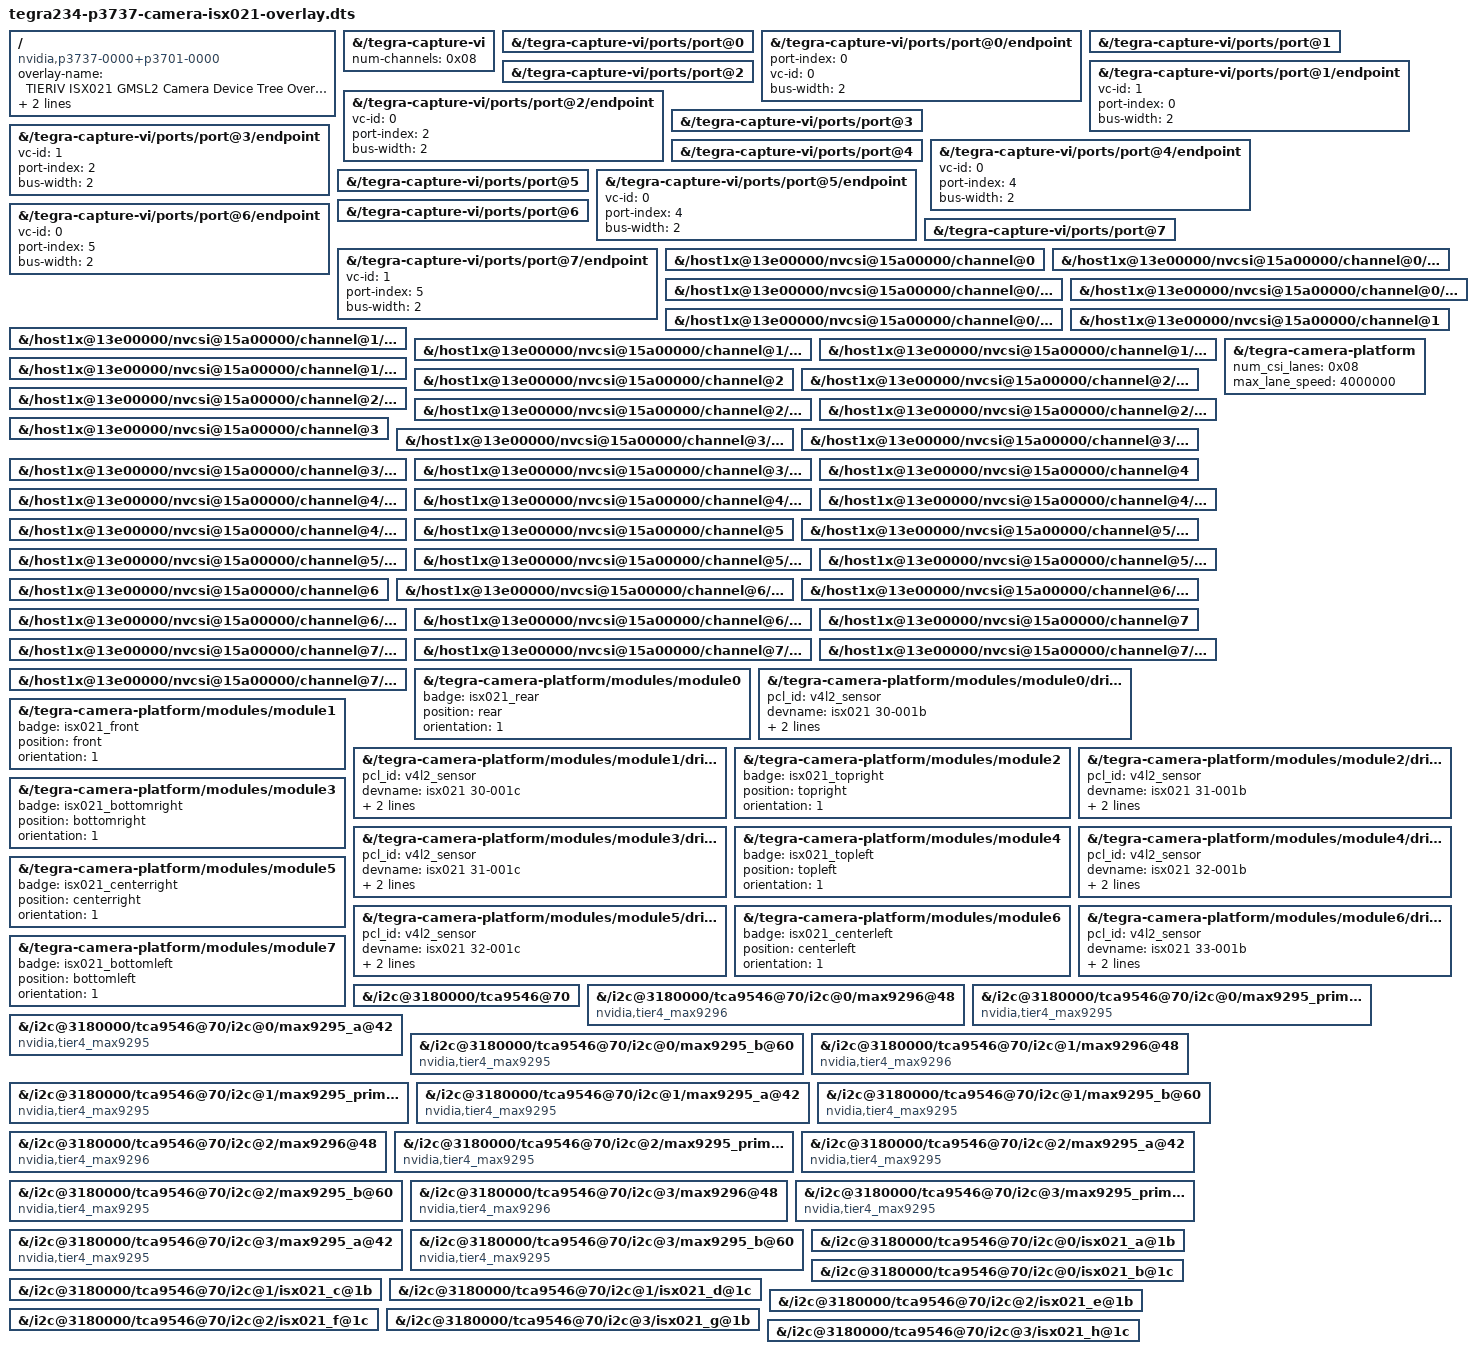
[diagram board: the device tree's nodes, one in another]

/dts-v1/;
/plugin/;

#include "dt-bindings/clock/tegra234-clock.h"

/ {
  overlay-name = "TIERIV ISX021 GMSL2 Camera Device Tree Overlay";
  jetson-header-name = "Jetson AGX Xavier CSI Connector";
  compatible = "nvidia,p3737-0000+p3701-0000", "nvidia,tegra234", "nvidia,tegra23x";

  fragment@1 {
    target-path = "/tegra-capture-vi";
    __overlay__ {
      num-channels = <0x08>;
    };
  };

  fragment@2 {
    target-path = "/tegra-capture-vi/ports/port@0";
    __overlay__ {
      status = "okay";
    
  };
  };
  
  fragment@3 {
    target-path = "/tegra-capture-vi/ports/port@0/endpoint";
    __overlay__ {
      status = "okay";
      port-index = <0>;
      vc-id = <0>;
      bus-width = <2>;
    };
  };
  
  fragment@4 {
    target-path = "/tegra-capture-vi/ports/port@1";
    __overlay__ {
      status = "okay";
    };
  };
  
  fragment@5 {
    target-path = "/tegra-capture-vi/ports/port@1/endpoint";
    __overlay__ {
      status = "okay";
      vc-id = <1>;
      port-index = <0>;
      bus-width = <2>;
    };
  };

  fragment@6 {
    target-path = "/tegra-capture-vi/ports/port@2";
    __overlay__ {
      status = "okay";
    
  };
  };
  
  fragment@7 {
    target-path = "/tegra-capture-vi/ports/port@2/endpoint";
    __overlay__ {
      status = "okay";
      vc-id = <0>;
      port-index = <2>;
      bus-width = <2>;
    };
  };
  
  fragment@8 {
    target-path = "/tegra-capture-vi/ports/port@3";
    __overlay__ {
      status = "okay";
    };
  };
  
  fragment@9 {
    target-path = "/tegra-capture-vi/ports/port@3/endpoint";
    __overlay__ {
      status = "okay";
      vc-id = <1>;
      port-index = <2>;
      bus-width = <2>;
    };
  };
  
  fragment@10 {
    target-path = "/tegra-capture-vi/ports/port@4";
    __overlay__ {
      status = "okay";
    
  };
  };
  
  fragment@11 {
    target-path = "/tegra-capture-vi/ports/port@4/endpoint";
    __overlay__ {
      status = "okay";
      vc-id = <0>;
      port-index = <4>;
      bus-width = <2>;
    };
  };
  
  fragment@12 {
    target-path = "/tegra-capture-vi/ports/port@5";
    __overlay__ {
      status = "okay";
    };
  };

  fragment@13 {
    target-path = "/tegra-capture-vi/ports/port@5/endpoint";
    __overlay__ {
      status = "okay";
      vc-id = <0>;
      port-index = <4>;
      bus-width = <2>;
    };
  };
  
  fragment@14 {
    target-path = "/tegra-capture-vi/ports/port@6";
    __overlay__ {
      status = "okay";
    };
  };
  
  fragment@15 {
    target-path = "/tegra-capture-vi/ports/port@6/endpoint";
    __overlay__ {
      status = "okay";
      vc-id = <0>;
      port-index = <5>;
      bus-width = <2>;
    };
  };
  
  fragment@16 {
    target-path = "/tegra-capture-vi/ports/port@7";
    __overlay__ {
      status = "okay";
    };
  };
  
  
  fragment@17 {
    target-path = "/tegra-capture-vi/ports/port@7/endpoint";
    __overlay__ {
      status = "okay";
      vc-id = <1>;
      port-index = <5>;
      bus-width = <2>;
    };
  };

  // nvcsi
  // channel 0
  fragment@18 {
    target-path = "/host1x@13e00000/nvcsi@15a00000/channel@0";
    __overlay__ {
      status = "okay";
    };
  };
  fragment@19 {
    target-path = "/host1x@13e00000/nvcsi@15a00000/channel@0/ports/port@0";
    __overlay__ {
      status = "okay";
    };
  };
  fragment@20 {
    // target = csi_in0
    target-path = "/host1x@13e00000/nvcsi@15a00000/channel@0/ports/port@0/endpoint@0";
    __overlay__ {
      status = "okay";
    };
  };
  
  fragment@21 {
    target-path = "/host1x@13e00000/nvcsi@15a00000/channel@0/ports/port@1";
    __overlay__ {
      status = "okay";
    };
  };

  fragment@22 {
    // target = csi_out0
    target-path = "/host1x@13e00000/nvcsi@15a00000/channel@0/ports/port@1/endpoint@1";
    __overlay__ {
      status = "okay";
    };
  };

  // channel 1
  fragment@23 {
    target-path = "/host1x@13e00000/nvcsi@15a00000/channel@1";
    __overlay__ {
      status = "okay";
    };
  };
  fragment@24 {
    target-path = "/host1x@13e00000/nvcsi@15a00000/channel@1/ports/port@0";
    __overlay__ {
      status = "okay";
    };
  };
  fragment@25 {
    // target = csi_in0
    target-path = "/host1x@13e00000/nvcsi@15a00000/channel@1/ports/port@0/endpoint@2";
    __overlay__ {
      status = "okay";
    };
  };
  
  fragment@26 {
    target-path = "/host1x@13e00000/nvcsi@15a00000/channel@1/ports/port@1";
    __overlay__ {
      status = "okay";
    };
  };

  fragment@27 {
    // target = csi_out0
    target-path = "/host1x@13e00000/nvcsi@15a00000/channel@1/ports/port@1/endpoint@3";
    __overlay__ {
      status = "okay";
    };
  };

  // channel@2
  fragment@28 {
    target-path = "/host1x@13e00000/nvcsi@15a00000/channel@2";
    __overlay__ {
      status = "okay";
    };
  };
  fragment@29 {
    target-path = "/host1x@13e00000/nvcsi@15a00000/channel@2/ports/port@0";
    __overlay__ {
      status = "okay";
    };
  };
  fragment@30 {
    // target = csi_in0
    target-path = "/host1x@13e00000/nvcsi@15a00000/channel@2/ports/port@0/endpoint@4";
    __overlay__ {
      status = "okay";
    };
  };
  
  fragment@31 {
    target-path = "/host1x@13e00000/nvcsi@15a00000/channel@2/ports/port@1";
    __overlay__ {
      status = "okay";
    };
  };

  fragment@32 {
    // target = csi_out0
    target-path = "/host1x@13e00000/nvcsi@15a00000/channel@2/ports/port@1/endpoint@5";
    __overlay__ {
      status = "okay";
    };
  };

  // channel@3
  fragment@33 {
    target-path = "/host1x@13e00000/nvcsi@15a00000/channel@3";
    __overlay__ {
      status = "okay";
    };
  };
  fragment@34 {
    target-path = "/host1x@13e00000/nvcsi@15a00000/channel@3/ports/port@0";
    __overlay__ {
      status = "okay";
    };
  };
  fragment@35 {
    // target = csi_in0
    target-path = "/host1x@13e00000/nvcsi@15a00000/channel@3/ports/port@0/endpoint@6";
    __overlay__ {
      status = "okay";
    };
  };
  
  fragment@36 {
    target-path = "/host1x@13e00000/nvcsi@15a00000/channel@3/ports/port@1";
    __overlay__ {
      status = "okay";
    };
  };

  fragment@37 {
    // target = csi_out0
    target-path = "/host1x@13e00000/nvcsi@15a00000/channel@3/ports/port@1/endpoint@7";
    __overlay__ {
      status = "okay";
    };
  };

  // channel@4
  fragment@38 {
    target-path = "/host1x@13e00000/nvcsi@15a00000/channel@4";
    __overlay__ {
      status = "okay";
    };
  };
  fragment@39 {
    target-path = "/host1x@13e00000/nvcsi@15a00000/channel@4/ports/port@0";
    __overlay__ {
      status = "okay";
    };
  };
  fragment@40 {
    // target = csi_in0
    target-path = "/host1x@13e00000/nvcsi@15a00000/channel@4/ports/port@0/endpoint@8";
    __overlay__ {
      status = "okay";
    };
  };
  
  fragment@41 {
    target-path = "/host1x@13e00000/nvcsi@15a00000/channel@4/ports/port@1";
    __overlay__ {
      status = "okay";
    };
  };

  fragment@42 {
    // target = csi_out0
    target-path = "/host1x@13e00000/nvcsi@15a00000/channel@4/ports/port@1/endpoint@9";
    __overlay__ {
      status = "okay";
    };
  };

  // channel@5
  fragment@43 {
    target-path = "/host1x@13e00000/nvcsi@15a00000/channel@5";
    __overlay__ {
      status = "okay";
    };
  };
  fragment@44 {
    target-path = "/host1x@13e00000/nvcsi@15a00000/channel@5/ports/port@0";
    __overlay__ {
      status = "okay";
    };
  };
  fragment@45 {
    // target = csi_in0
    target-path = "/host1x@13e00000/nvcsi@15a00000/channel@5/ports/port@0/endpoint@10";
    __overlay__ {
      status = "okay";
    };
  };
  
  fragment@46 {
    target-path = "/host1x@13e00000/nvcsi@15a00000/channel@5/ports/port@1";
    __overlay__ {
      status = "okay";
    };
  };

  fragment@47 {
    // target = csi_out0
    target-path = "/host1x@13e00000/nvcsi@15a00000/channel@5/ports/port@1/endpoint@11";
    __overlay__ {
      status = "okay";
    };
  };

  // channel@6
  fragment@48 {
    target-path = "/host1x@13e00000/nvcsi@15a00000/channel@6";
    __overlay__ {
      status = "okay";
    };
  };
  fragment@49 {
    target-path = "/host1x@13e00000/nvcsi@15a00000/channel@6/ports/port@0";
    __overlay__ {
      status = "okay";
    };
  };
  fragment@50 {
    // target = csi_in0
    target-path = "/host1x@13e00000/nvcsi@15a00000/channel@6/ports/port@0/endpoint@10";
    __overlay__ {
      status = "okay";
    };
  };
  
  fragment@51 {
    target-path = "/host1x@13e00000/nvcsi@15a00000/channel@6/ports/port@1";
    __overlay__ {
      status = "okay";
    };
  };

  fragment@52 {
    // target = csi_out0
    target-path = "/host1x@13e00000/nvcsi@15a00000/channel@6/ports/port@1/endpoint@11";
    __overlay__ {
      status = "okay";
    };
  };
  
  // channel@7
  fragment@53 {
    target-path = "/host1x@13e00000/nvcsi@15a00000/channel@7";
    __overlay__ {
      status = "okay";
    };
  };
  fragment@54 {
    target-path = "/host1x@13e00000/nvcsi@15a00000/channel@7/ports/port@0";
    __overlay__ {
      status = "okay";
    };
  };
  fragment@55 {
    // target = csi_in0
    target-path = "/host1x@13e00000/nvcsi@15a00000/channel@7/ports/port@0/endpoint@14";
    __overlay__ {
      status = "okay";
    };
  };
  
  fragment@56 {
    target-path = "/host1x@13e00000/nvcsi@15a00000/channel@7/ports/port@1";
    __overlay__ {
      status = "okay";
    };
  };

  fragment@57 {
    // target = csi_out0
    target-path = "/host1x@13e00000/nvcsi@15a00000/channel@7/ports/port@1/endpoint@15";
    __overlay__ {
      status = "okay";
    };
  };


  ////////////////////////////////////
  fragment@58 {
    //tcp
    target-path = "/tegra-camera-platform";
    __overlay__ {
      num_csi_lanes = <0x08>;
      max_lane_speed = <4000000>;
    };
  };


  fragment@59 {
    target-path = "/tegra-camera-platform/modules/module0";
    __overlay__ {
      badge = "isx021_rear";
      position = "rear";
      orientation = "1";
      status = "okay";
    };
  };

  fragment@60 {
    target-path = "/tegra-camera-platform/modules/module0/drivernode0";
    __overlay__ {
      status = "okay";
      pcl_id = "v4l2_sensor";
      devname = "isx021 30-001b";
      proc-device-tree = "/proc/device-tree/i2c@3180000/tca9546@70/i2c@0/isx021_a@1b";
    };
  };

  fragment@61 {
    target-path = "/tegra-camera-platform/modules/module1";
    __overlay__ {
      badge = "isx021_front";
      position = "front";
      orientation = "1";
      status = "okay";
    };
  };

  fragment@62 {
    target-path = "/tegra-camera-platform/modules/module1/drivernode0";
    __overlay__ {
    status = "okay";
    pcl_id = "v4l2_sensor";
    devname = "isx021 30-001c";
    proc-device-tree = "/proc/device-tree/i2c@3180000/tca9546@70/i2c@0/isx021_b@1c";
    };
  };

  fragment@63 {
    target-path = "/tegra-camera-platform/modules/module2";
    __overlay__ {
      badge = "isx021_topright";
      position = "topright";
      orientation = "1";
      status = "okay";
    };
  };

  fragment@64 {
    target-path = "/tegra-camera-platform/modules/module2/drivernode0";
    __overlay__ {
    status = "okay";
    pcl_id = "v4l2_sensor";
    devname = "isx021 31-001b";
    proc-device-tree = "/proc/device-tree/i2c@3180000/tca9546@70/i2c@1/isx021_c@1b";
    };
  };

  fragment@65 {
    target-path = "/tegra-camera-platform/modules/module3";
    __overlay__ {
      badge = "isx021_bottomright";
      position = "bottomright";
      orientation = "1";
      status = "okay";
    };
  };

  fragment@66 {
    target-path = "/tegra-camera-platform/modules/module3/drivernode0";
    __overlay__ {
    status = "okay";
    pcl_id = "v4l2_sensor";
    devname = "isx021 31-001c";
    proc-device-tree = "/proc/device-tree/i2c@3180000/tca9546@70/i2c@1/isx021_d@1c";
    };
  };

  fragment@67 {
    target-path = "/tegra-camera-platform/modules/module4";
    __overlay__ {
      badge = "isx021_topleft";
      position = "topleft";
      orientation = "1";
      status = "okay";
    };
  };

  fragment@68 {
    target-path = "/tegra-camera-platform/modules/module4/drivernode0";
    __overlay__ {
    status = "okay";
    pcl_id = "v4l2_sensor";
    devname = "isx021 32-001b";
    proc-device-tree = "/proc/device-tree/i2c@3180000/tca9546@70/i2c@2/isx021_e@1b";
    };
  };

  fragment@69 {
    target-path = "/tegra-camera-platform/modules/module5";
    __overlay__ {
      badge = "isx021_centerright";
      position = "centerright";
      orientation = "1";
      status = "okay";
    };
  };

  fragment@70 {
    target-path = "/tegra-camera-platform/modules/module5/drivernode0";
    __overlay__ {
    status = "okay";
    pcl_id = "v4l2_sensor";
    devname = "isx021 32-001c";
    proc-device-tree = "/proc/device-tree/i2c@3180000/tca9546@70/i2c@2/isx021_f@1c";
    };
  };

  fragment@71 {
    target-path = "/tegra-camera-platform/modules/module6";
    __overlay__ {
      badge = "isx021_centerleft";
      position = "centerleft";
      orientation = "1";
      status = "okay";
    };
  };

  fragment@72 {
    target-path = "/tegra-camera-platform/modules/module6/drivernode0";
    __overlay__ {
      status = "okay";
      pcl_id = "v4l2_sensor";
      devname = "isx021 33-001b";
      proc-device-tree = "/proc/device-tree/i2c@3180000/tca9546@70/i2c@3/isx021_g@1b";
    };
  };

  fragment@73 {
    target-path = "/tegra-camera-platform/modules/module7";
    __overlay__ {
      badge = "isx021_bottomleft";
      position = "bottomleft";
      orientation = "1";
      status = "okay";
    };
  };

  fragment@74 {
    target-path = "/tegra-camera-platform/modules/module1/drivernode0";
    __overlay__ {
    status = "okay";
    pcl_id = "v4l2_sensor";
    devname = "isx021 30-001c";
    proc-device-tree = "/proc/device-tree/i2c@3180000/tca9546@70/i2c@0/isx021_b@1c";
    };
  };


  // cam
  fragment@75 {
    //cami2c/i2c@0
    target-path = "/i2c@3180000/tca9546@70";
    __overlay__ {
      status = "okay";
    };
  };

  // i2c@0
  fragment@76 {
    //cami2c/i2c@0
    target-path = "/i2c@3180000/tca9546@70/i2c@0/max9296@48";
    __overlay__ {
      status = "okay";
      compatible = "nvidia,tier4_max9296";
    };
  };

  fragment@77 {
    //cami2c/i2c@0
    target-path = "/i2c@3180000/tca9546@70/i2c@0/max9295_prim@62";
    __overlay__ {
      status = "okay";
      compatible = "nvidia,tier4_max9295";
    };
  };

  fragment@78 {
    //cami2c/i2c@0
    target-path = "/i2c@3180000/tca9546@70/i2c@0/max9295_a@42";
    __overlay__ {
      status = "okay";
      compatible = "nvidia,tier4_max9295";
    };
  };

  fragment@79 {
    //cami2c/i2c@0
    target-path = "/i2c@3180000/tca9546@70/i2c@0/max9295_b@60";
    __overlay__ {
      status = "okay";
      compatible = "nvidia,tier4_max9295";
    };
  };

  // i2c@1
  fragment@80 {
    //cami2c/i2c@1
    target-path = "/i2c@3180000/tca9546@70/i2c@1/max9296@48";
    __overlay__ {
      status = "okay";
      compatible = "nvidia,tier4_max9296";
    };
  };

  fragment@81 {
    //cami2c/i2c@1
    target-path = "/i2c@3180000/tca9546@70/i2c@1/max9295_prim@62";
    __overlay__ {
      status = "okay";
      compatible = "nvidia,tier4_max9295";
    };
  };

  fragment@82 {
    //cami2c/i2c@1
    target-path = "/i2c@3180000/tca9546@70/i2c@1/max9295_a@42";
    __overlay__ {
      status = "okay";
      compatible = "nvidia,tier4_max9295";
    };
  };

  fragment@83 {
    //cami2c/i2c@1
    target-path = "/i2c@3180000/tca9546@70/i2c@1/max9295_b@60";
    __overlay__ {
      status = "okay";
      compatible = "nvidia,tier4_max9295";
    };
  };

  // i2c@2
  fragment@84 {
    //cami2c/i2c@2
    target-path = "/i2c@3180000/tca9546@70/i2c@2/max9296@48";
    __overlay__ {
      status = "okay";
      compatible = "nvidia,tier4_max9296";
    };
  };

  fragment@85 {
    //cami2c/i2c@2
    target-path = "/i2c@3180000/tca9546@70/i2c@2/max9295_prim@62";
    __overlay__ {
      status = "okay";
      compatible = "nvidia,tier4_max9295";
    };
  };

  fragment@86 {
    //cami2c/i2c@2
    target-path = "/i2c@3180000/tca9546@70/i2c@2/max9295_a@42";
    __overlay__ {
      status = "okay";
      compatible = "nvidia,tier4_max9295";
    };
  };

  fragment@87 {
    //cami2c/i2c@2
    target-path = "/i2c@3180000/tca9546@70/i2c@2/max9295_b@60";
    __overlay__ {
      status = "okay";
      compatible = "nvidia,tier4_max9295";
    };
  };

  // i2c@3
  fragment@88 {
    //cami2c/i2c@3
    target-path = "/i2c@3180000/tca9546@70/i2c@3/max9296@48";
    __overlay__ {
      status = "okay";
      compatible = "nvidia,tier4_max9296";
    };
  };

  fragment@89 {
    //cami2c/i2c@3
    target-path = "/i2c@3180000/tca9546@70/i2c@3/max9295_prim@62";
    __overlay__ {
      status = "okay";
      compatible = "nvidia,tier4_max9295";
    };
  };

  fragment@90 {
    //cami2c/i2c@3
    target-path = "/i2c@3180000/tca9546@70/i2c@3/max9295_a@42";
    __overlay__ {
      status = "okay";
      compatible = "nvidia,tier4_max9295";
    };
  };

  fragment@91 {
    //cami2c/i2c@3
    target-path = "/i2c@3180000/tca9546@70/i2c@3/max9295_b@60";
    __overlay__ {
      status = "okay";
      compatible = "nvidia,tier4_max9295";
    };
  };

  fragment@92 {
    target-path = "/i2c@3180000/tca9546@70/i2c@0/isx021_a@1b";
    __overlay__ {
      status = "okay";
    };
  };
  fragment@93 {
    target-path = "/i2c@3180000/tca9546@70/i2c@0/isx021_b@1c";
    __overlay__ {
      status = "okay";
    };
  };
  fragment@94 {
    target-path = "/i2c@3180000/tca9546@70/i2c@1/isx021_c@1b";
    __overlay__ {
      status = "okay";
    };
  };
  fragment@95 {
    target-path = "/i2c@3180000/tca9546@70/i2c@1/isx021_d@1c";
    __overlay__ {
      status = "okay";
    };
  };
  fragment@96 {
    target-path = "/i2c@3180000/tca9546@70/i2c@2/isx021_e@1b";
    __overlay__ {
      status = "okay";
    };
  };
  fragment@97 {
    target-path = "/i2c@3180000/tca9546@70/i2c@2/isx021_f@1c";
    __overlay__ {
      status = "okay";
    };
  };
  fragment@98 {
    target-path = "/i2c@3180000/tca9546@70/i2c@3/isx021_g@1b";
    __overlay__ {
      status = "okay";
    };
  };
  fragment@99 {
    target-path = "/i2c@3180000/tca9546@70/i2c@3/isx021_h@1c";
    __overlay__ {
      status = "okay";
    };
  };


};
